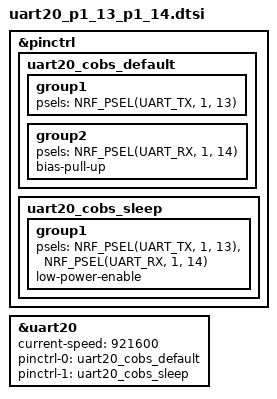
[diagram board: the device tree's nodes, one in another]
/*
 * Shared uart20 COBS-UART pinctrl + enable for boards that route the COBS
 * ranging stream to P1.13 (TX) / P1.14 (RX) at 921600 baud. Included by the
 * board overlays that use this pinout (currently nrf54l15tag and fanstel_bm15c).
 * Both expose the COBS stream on these pins via an external UART-to-USB adapter
 * (e.g. FT232R).
 *
 * The pinctrl groups use unique `uart20_cobs_*` labels (not `uart20_*`) so they
 * define fresh nodes rather than merging into a board base's `uart20_default`/
 * `uart20_sleep`. The fanstel overlay builds on the nrf54l15dk base, whose own
 * `uart20_sleep` carries a `group2` for P1.04; reusing the base labels would let
 * that `group2` survive the merge and leak P1.04 into the fanstel sleep state.
 * The unique labels leave the base groups unreferenced so `/omit-if-no-ref/`
 * drops them.
 *
 * SPDX-License-Identifier: MIT
 */

&pinctrl {
	/omit-if-no-ref/ uart20_cobs_default: uart20_cobs_default {
		group1 {
			psels = <NRF_PSEL(UART_TX, 1, 13)>;
		};
		group2 {
			psels = <NRF_PSEL(UART_RX, 1, 14)>;
			bias-pull-up;
		};
	};

	/omit-if-no-ref/ uart20_cobs_sleep: uart20_cobs_sleep {
		group1 {
			psels = <NRF_PSEL(UART_TX, 1, 13)>,
				<NRF_PSEL(UART_RX, 1, 14)>;
			low-power-enable;
		};
	};
};

&uart20 {
	status = "okay";
	current-speed = <921600>;
	pinctrl-0 = <&uart20_cobs_default>;
	pinctrl-1 = <&uart20_cobs_sleep>;
	pinctrl-names = "default", "sleep";
};
